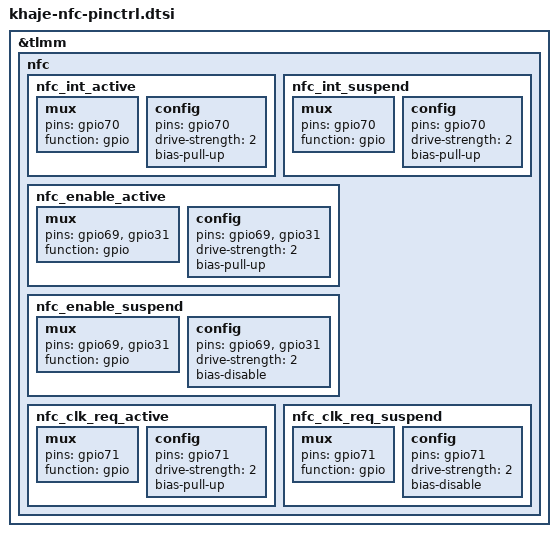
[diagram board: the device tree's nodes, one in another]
&tlmm {
	nfc {
		nfc_int_active: nfc_int_active {
			/* active state */
			mux {
				/* GPIO 70 NFC Read Interrupt */
				pins = "gpio70";
				function = "gpio";
			};

			config {
				pins = "gpio70";
				drive-strength = <2>; /* 2 MA */
				bias-pull-up;
			};
		};

		nfc_int_suspend: nfc_int_suspend {
			/* sleep state */
			mux {
				/* GPIO 70 NFC Read Interrupt */
				pins = "gpio70";
				function = "gpio";
			};

			config {
				pins = "gpio70";
				drive-strength = <2>; /* 2 MA */
				bias-pull-up;
			};
		};

		nfc_enable_active: nfc_enable_active {
			/* active state */
			mux {
				/* 69: Enable 31: Firmware */
				pins = "gpio69", "gpio31";
				function = "gpio";
			};

			config {
				pins = "gpio69", "gpio31";
				drive-strength = <2>; /* 2 MA */
				bias-pull-up;
			};
		};

		nfc_enable_suspend: nfc_enable_suspend {
			/* sleep state */
			mux {
				/* 69: Enable 31: Firmware */
				pins = "gpio69", "gpio31";
				function = "gpio";
			};

			config {
				pins = "gpio69", "gpio31";
				drive-strength = <2>; /* 2 MA */
				bias-disable;
			};
		};

		nfc_clk_req_active: nfc_clk_req_active {
			/* active state */
			mux {
				/* GPIO 71: NFC CLOCK REQUEST */
				pins = "gpio71";
				function = "gpio";
			};

			config {
				pins = "gpio71";
				drive-strength = <2>; /* 2 MA */
				bias-pull-up;
			};
		};

		nfc_clk_req_suspend: nfc_clk_req_suspend {
			/* sleep state */
			mux {
				/* GPIO 71: NFC CLOCK REQUEST */
				pins = "gpio71";
				function = "gpio";
			};

			config {
				pins = "gpio71";
				drive-strength = <2>; /* 2 MA */
				bias-disable;
			};
		};
	};
}; //tlmm
